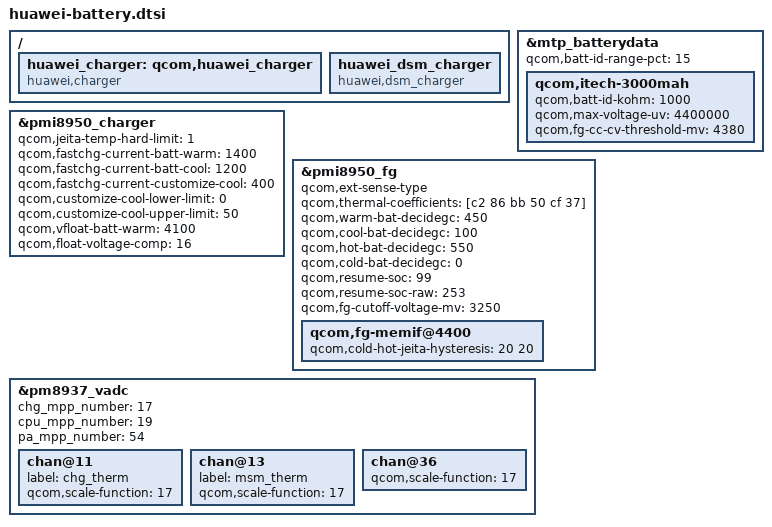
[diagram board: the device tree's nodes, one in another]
&mtp_batterydata {
	qcom,batt-id-range-pct = <15>;

	qcom,itech-3000mah {
		qcom,batt-id-kohm = <1000>;
		qcom,max-voltage-uv = <4400000>;
		qcom,fg-cc-cv-threshold-mv = <4380>;
	};
	#include "../HB406689ECW_ATL_Desay_4v4_4000mah.dtsi"
};

&pmi8950_charger {
	/* jeita parameters */
	qcom,jeita-temp-hard-limit = <1>;
	qcom,fastchg-current-batt-warm = <1400>;
	qcom,fastchg-current-batt-cool = <1200>;
	qcom,fastchg-current-customize-cool = <400>;
	qcom,customize-cool-lower-limit = <0>;
	qcom,customize-cool-upper-limit = <50>;
	qcom,vfloat-batt-warm = <4100>;
	qcom,float-voltage-comp = <16>;
};

&pmi8950_fg {
	/* Using external sense */
	qcom,ext-sense-type;
	/* set Beta value */
	qcom,thermal-coefficients = [c2 86 bb 50 cf 37];
	/* set temp range thershold */
	qcom,warm-bat-decidegc = <450>;
	qcom,cool-bat-decidegc = <100>;
	qcom,hot-bat-decidegc = <550>;
	qcom,cold-bat-decidegc = <0>;
	qcom,resume-soc = <99>;
	qcom,resume-soc-raw = <253>;
	qcom,fg-cutoff-voltage-mv = <3250>;
	qcom,fg-memif@4400 {
		qcom,cold-hot-jeita-hysteresis = <20 20>;
	};
};

/{
	huawei_charger: qcom,huawei_charger{
		compatible = "huawei,charger";
		status = "okay";
	};
};

/{
	huawei_dsm_charger: huawei_dsm_charger{
		compatible = "huawei,dsm_charger";
		status = "ok";
	};
};

&pm8937_vadc {
	chg_mpp_number = <17>;
	cpu_mpp_number = <19>;
	pa_mpp_number = <54>;

	chan@11 {
		label = "chg_therm";
		qcom,scale-function = <17>;
	};
	chan@13 {
		label = "msm_therm";
		qcom,scale-function = <17>;
	};
	chan@36 {
		qcom,scale-function = <17>;
	};
};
